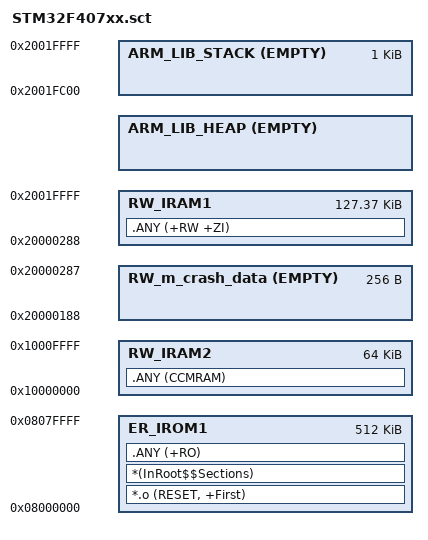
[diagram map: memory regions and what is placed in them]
#! armcc -E
; *****************************************
; *** Scatter-Loading Description File  ***
; *****************************************

#if !defined(MBED_APP_START)
  #define MBED_APP_START            0x08000000
#endif

#if !defined(MBED_APP_SIZE)
  #define MBED_APP_SIZE             0x00080000
#endif

#if !defined(MBED_RAM_START)
  #define MBED_RAM_START            0x20000000
#endif

#if !defined(MBED_RAM_SIZE)
  #define MBED_RAM_SIZE             0x00020000
#endif


#define MBED_RAM2_START             0x10000000
#define MBED_RAM2_SIZE              0x00010000

#if !defined(MBED_BOOT_STACK_SIZE)
  #define MBED_BOOT_STACK_SIZE      0x400
#endif

#define VECTOR_SIZE                 0x188

#define MBED_CRASH_REPORT_RAM_SIZE  0x100

#define MBED_IRAM1_START             (MBED_RAM_START + VECTOR_SIZE + MBED_CRASH_REPORT_RAM_SIZE)
#define MBED_IRAM1_SIZE              (MBED_RAM_SIZE - VECTOR_SIZE - MBED_CRASH_REPORT_RAM_SIZE)


#define RAM_FIXED_SIZE              (MBED_BOOT_STACK_SIZE+VECTOR_SIZE+MBED_CRASH_REPORT_RAM_SIZE)

LR_IROM1  MBED_APP_START  MBED_APP_SIZE  {    ; load region size_region

  ER_IROM1  MBED_APP_START  MBED_APP_SIZE  {  ; load address = execution address
   *.o (RESET, +First)
   *(InRoot$$Sections)
   .ANY (+RO)
  }

  RW_m_crash_data  (MBED_RAM_START+VECTOR_SIZE)  EMPTY MBED_CRASH_REPORT_RAM_SIZE { ; RW data
  }

  RW_IRAM1  MBED_IRAM1_START  MBED_IRAM1_SIZE  {  ; RW data
   .ANY (+RW +ZI)
  }

  ARM_LIB_HEAP  AlignExpr(+0, 16)  EMPTY  (MBED_RAM_SIZE-RAM_FIXED_SIZE+MBED_RAM_START-AlignExpr(ImageLimit(RW_IRAM1), 16))  {
  }

  RW_IRAM2  MBED_RAM2_START  MBED_RAM2_SIZE  {  ; CCM
   .ANY (CCMRAM)
  }

  ARM_LIB_STACK  (MBED_RAM_START+MBED_RAM_SIZE)  EMPTY  -MBED_BOOT_STACK_SIZE { ; stack
  }
}
